# ATmega32C1 register map
Vendor: Atmel; File version: 1.0
CPU: other r0p0, little endian, no MPU, no FPU, 4 interrupt priority bits
Registers are 8-bit, read-write, reset 0x0 unless marked. A register's access mark holds for its fields unless they carry their own. Offsets are from the block's base; [hi:lo] are bit positions.

## CAN — Controller Area Network
Base 0x008000D8
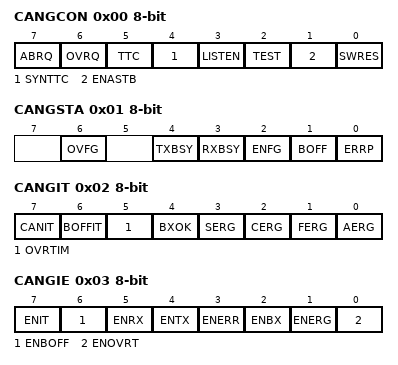
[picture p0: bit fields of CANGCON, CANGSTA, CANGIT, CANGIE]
0x00 CANGCON — CAN General Control Register
  [7] ABRQ — Abort Request
  [6] OVRQ — Overload Frame Request
  [5] TTC — Time Trigger Communication
  [4] SYNTTC — Synchronization of TTC
  [3] LISTEN — Listening Mode
  [2] TEST — Test Mode
  [1] ENASTB — Enable / Standby
  [0] SWRES — Software Reset Request
0x01 CANGSTA — CAN General Status Register (read-only for debugger)
  [6] OVFG — Overload Frame Flag
  [4] TXBSY — Transmitter Busy
  [3] RXBSY — Receiver Busy
  [2] ENFG — Enable Flag
  [1] BOFF — Bus Off Mode
  [0] ERRP — Error Passive Mode
0x02 CANGIT — CAN General Interrupt Register Flags
  [7] CANIT — General Interrupt Flag
  [6] BOFFIT — Bus Off Interrupt Flag
  [5] OVRTIM — Overrun CAN Timer Flag
  [4] BXOK — Burst Receive Interrupt Flag
  [3] SERG — Stuff Error General Flag
  [2] CERG — CRC Error General Flag
  [1] FERG — Form Error General Flag
  [0] AERG — Acknowledgement Error General Flag
0x03 CANGIE — CAN General Interrupt Enable Register
  [7] ENIT — Enable all Interrupts
  [6] ENBOFF — Enable Bus Off Interrupt
  [5] ENRX — Enable Receive Interrupt
  [4] ENTX — Enable Transmit Interrupt
  [3] ENERR — Enable MOb Error Interrupt
  [2] ENBX — Enable Burst Receive Interrupt
  [1] ENERG — Enable General Error Interrupt
  [0] ENOVRT — Enable CAN Timer Overrun Interrupt
0x04 CANEN2 — Enable MOb Register 2 (read-only for debugger)
  [5:0] ENMOB — Enable MObs
0x05 CANEN1 — Enable MOb Register 1(empty)
0x06 CANIE2 — Enable Interrupt MOb Register 2
  [5:0] IEMOB — Interrupt Enable MObs
0x07 CANIE1 — Enable Interrupt MOb Register 1 (empty)
0x08 CANSIT2 — CAN Status Interrupt MOb Register 2 (read-only for debugger)
  [5:0] SIT — Status of Interrupt MObs
0x09 CANSIT1 — CAN Status Interrupt MOb Register 1 (empty)
0x0A CANBT1 — CAN Bit Timing Register 1
  [6:1] BRP — Baud Rate Prescaler bits
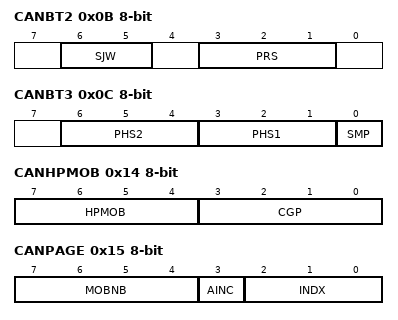
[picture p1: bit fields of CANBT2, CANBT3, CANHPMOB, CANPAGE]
0x0B CANBT2 — CAN Bit Timing Register 2
  [6:5] SJW — Re-Sync Jump Width bits
  [3:1] PRS — Propagation Time Segment bits
0x0C CANBT3 — CAN Bit Timing Register 3
  [6:4] PHS2 — Phase Segment 2 bits
  [3:1] PHS1 — Phase Segment 1 bits
  [0] SMP — Sample Type
0x0D CANTCON — Timer Control Register
  [7:0] TPRSC — Timer Control bits
0x0E CANTIM 16-bit (reset mask 0xFF) — Timer Register
  [15:0] CANTIM — CAN Timer bits
0x10 CANTTC 16-bit (reset mask 0xFF) — TTC Timer Register
  [15:0] TIMTTC — TTC Timer Count
0x12 CANTEC — Transmit Error Counter Register
  [7:0] TEC — Transmit Error Counter bits
0x13 CANREC — Receive Error Counter Register
  [7:0] REC — Receive Error Counter bits
0x14 CANHPMOB — Highest Priority MOb Register
  [7:4] HPMOB — Highest Priority MOb Number bits
  [3:0] CGP — CAN General Purpose bits
0x15 CANPAGE — Page MOb Register
  [7:4] MOBNB — MOb Number bits
  [3] AINC — MOb Data Buffer Auto Increment (Active Low)
  [2:0] INDX — Data Buffer Index bits
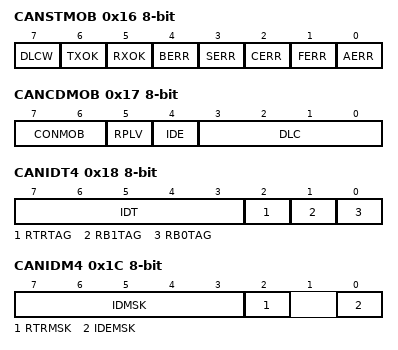
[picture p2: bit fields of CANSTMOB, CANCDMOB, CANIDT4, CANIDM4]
0x16 CANSTMOB — MOb Status Register
  [7] DLCW — Data Length Code Warning on MOb
  [6] TXOK — Transmit OK on MOb
  [5] RXOK — Receive OK on MOb
  [4] BERR — Bit Error on MOb
  [3] SERR — Stuff Error on MOb
  [2] CERR — CRC Error on MOb
  [1] FERR — Form Error on MOb
  [0] AERR — Acknowledgement Error on MOb
0x17 CANCDMOB — MOb Control and DLC Register
  [7:6] CONMOB — MOb Config bits
  [5] RPLV — Reply Valid
  [4] IDE — Identifier Extension
  [3:0] DLC — Data Length Code bits
0x18 CANIDT4 — Identifier Tag Register 4
  [7:3] IDT — Identifier Tag
  [2] RTRTAG — Remote Transmission Request Tag
  [1] RB1TAG — Reserved Bit 1 Tag
  [0] RB0TAG — Reserved Bit 0 Tag
0x19 CANIDT3 — Identifier Tag Register 3
  [7:0] IDT — Identifier Tag
0x1A CANIDT2 — Identifier Tag Register 2
  [7:0] IDT — Identifier Tag
0x1B CANIDT1 — Identifier Tag Register 1
  [7:0] IDT — Identifier Tag
0x1C CANIDM4 — Identifier Mask Register 4
  [7:3] IDMSK — Identifier Mask
  [2] RTRMSK — Remote Transmission Request Mask
  [0] IDEMSK — Identifier Extension Mask
0x1D CANIDM3 — Identifier Mask Register 3
  [7:0] IDMSK — Identifier Mask
0x1E CANIDM2 — Identifier Mask Register 2
  [7:0] IDMSK — Identifier Mask
0x1F CANIDM1 — Identifier Mask Register 1
  [7:0] IDMSK — Identifier Mask
0x20 CANSTM 16-bit (reset mask 0xFF) — Time Stamp Register
  [15:0] TIMSTM
0x22 CANMSG — Message Data Register
  [7:0] MSG — Message Data bits
